# ATSAM4S2A register map
Vendor: Atmel; File version: 0
CPU: CM4 r0p1, selectable endian, no MPU, no FPU, 0x4 interrupt priority bits, 0x0 interrupts
Registers are 32-bit, read-write, reset 0x0 unless marked. A register's access mark holds for its fields unless they carry their own. Offsets are from the block's base; [hi:lo] are bit positions; {n}, {i} and the like mark numbered series.

## ADC — Analog-to-Digital Converter
Base 0x40038000; register names take the prefix ADC_
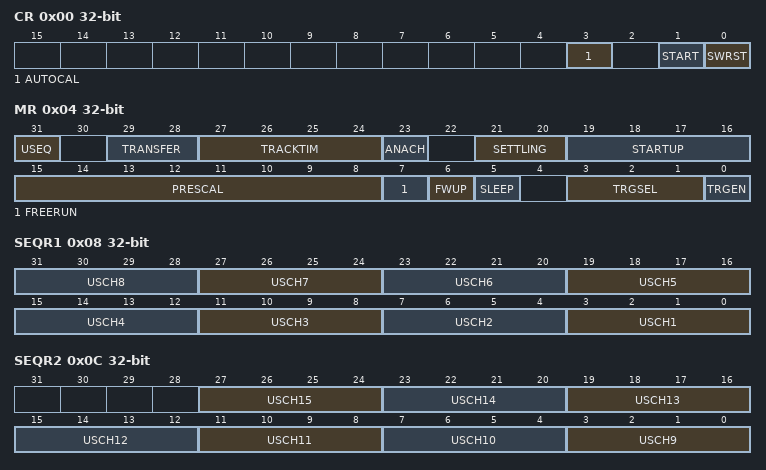
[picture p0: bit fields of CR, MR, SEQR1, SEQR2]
0x00 CR wo reset not defined — Control Register
  [3] AUTOCAL — Automatic Calibration of ADC
  [1] START — Start Conversion
  [0] SWRST — Software Reset
0x04 MR — Mode Register
  [31] USEQ — Use Sequence Enable
    0=NUM_ORDER (Normal Mode: The controller converts channels in a simple numeric order depending only on the channel index.); 1=REG_ORDER (User Sequence Mode: The sequence respects what is defined in ADC_SEQR1 and ADC_SEQR2 registers and can be used to convert the same channel several times.)
  [29:28] TRANSFER — Hold Time
  [27:24] TRACKTIM — Tracking Time
  [23] ANACH — Analog Change
    0=NONE (No analog change on channel switching: DIFF0, GAIN0 and OFF0 are used for all channels.); 1=ALLOWED (Allows different analog settings for each channel. See ADC_CGR and ADC_COR registers.)
  [21:20] SETTLING — Analog Settling Time
    0=AST3 (3 periods of ADCCLK); 1=AST5 (5 periods of ADCCLK); 2=AST9 (9 periods of ADCCLK); 3=AST17 (17 periods of ADCCLK)
  [19:16] STARTUP — Startup Time
    0=SUT0 (0 periods of ADCCLK); 1=SUT8 (8 periods of ADCCLK); 2=SUT16 (16 periods of ADCCLK); 3=SUT24 (24 periods of ADCCLK); 4=SUT64 (64 periods of ADCCLK); 5=SUT80 (80 periods of ADCCLK); 6=SUT96 (96 periods of ADCCLK); 7=SUT112 (112 periods of ADCCLK); 8=SUT512 (512 periods of ADCCLK); 9=SUT576 (576 periods of ADCCLK); 10=SUT640 (640 periods of ADCCLK); 11=SUT704 (704 periods of ADCCLK); 12=SUT768 (768 periods of ADCCLK); 13=SUT832 (832 periods of ADCCLK); 14=SUT896 (896 periods of ADCCLK); 15=SUT960 (960 periods of ADCCLK)
  [15:8] PRESCAL — Prescaler Rate Selection
  [7] FREERUN — Free Run Mode
    0=OFF (Normal Mode); 1=ON (Free Run Mode: Never wait for any trigger.)
  [6] FWUP — Fast Wake Up
    0=OFF (If SLEEP is 1, then both ADC core and reference voltage circuitry are OFF between conversions); 1=ON (If SLEEP is 1, then Fast Wake-up Sleep mode: The voltage reference is ON between conversions and ADC core is OFF)
  [5] SLEEP — Sleep Mode
    0=NORMAL (Normal Mode: The ADC core and reference voltage circuitry are kept ON between conversions.); 1=SLEEP (Sleep Mode: The wake-up time can be modified by programming FWUP bit.)
  [3:1] TRGSEL — Trigger Selection
    0=ADC_TRIG0 (External trigger); 1=ADC_TRIG1 (TIO Output of the Timer Counter Channel 0); 2=ADC_TRIG2 (TIO Output of the Timer Counter Channel 1); 3=ADC_TRIG3 (TIO Output of the Timer Counter Channel 2); 4=ADC_TRIG4 (PWM Event Line 0); 5=ADC_TRIG5 (PWM Event Line 1)
  [0] TRGEN — Trigger Enable
    0=DIS (Hardware triggers are disabled. Starting a conversion is only possible by software.); 1=EN (Hardware trigger selected by TRGSEL field is enabled.)
0x08 SEQR1 — Channel Sequence Register 1
  [4n-1:4n-4] USCH{n} (n=1..8) — User Sequence Number {n}
0x0C SEQR2 — Channel Sequence Register 2
  [4n-33:4n-36] USCH{n} (n=9..15) — User Sequence Number {n}
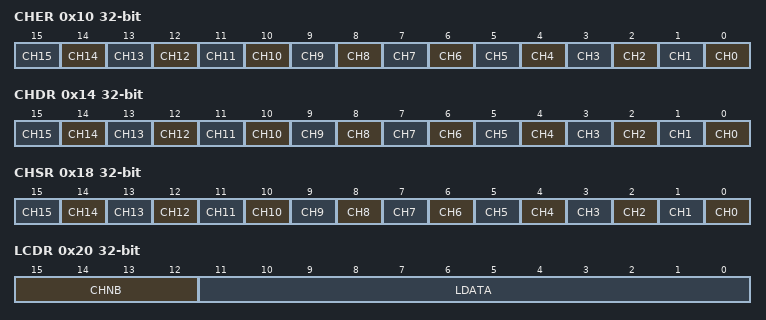
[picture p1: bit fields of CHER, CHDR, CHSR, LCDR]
0x10 CHER wo reset not defined — Channel Enable Register
  [n] CH{n} (n=0..15) — Channel {n} Enable
0x14 CHDR wo reset not defined — Channel Disable Register
  [n] CH{n} (n=0..15) — Channel {n} Disable
0x18 CHSR ro — Channel Status Register
  [n] CH{n} (n=0..15) — Channel {n} Status
0x20 LCDR ro — Last Converted Data Register
  [15:12] CHNB — Channel Number
  [11:0] LDATA — Last Data Converted
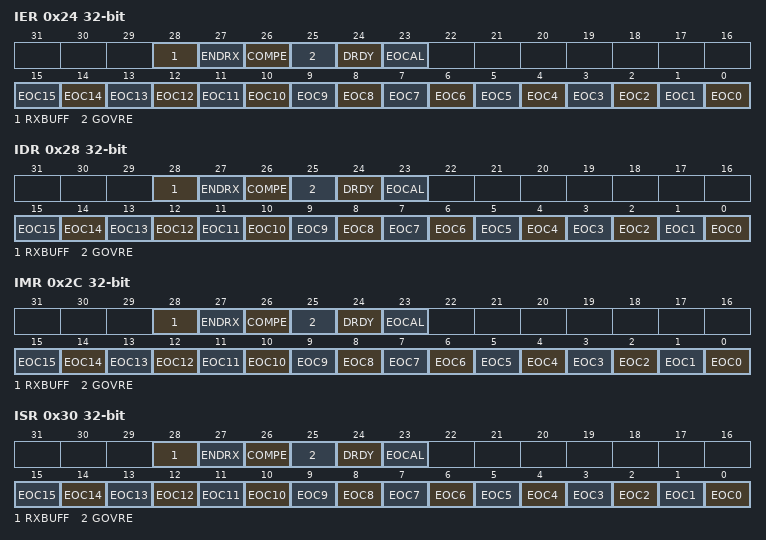
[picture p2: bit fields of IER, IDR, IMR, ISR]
0x24 IER wo reset not defined — Interrupt Enable Register
  [28] RXBUFF — Receive Buffer Full Interrupt Enable
  [27] ENDRX — End of Receive Buffer Interrupt Enable
  [26] COMPE — Comparison Event Interrupt Enable
  [25] GOVRE — General Overrun Error Interrupt Enable
  [24] DRDY — Data Ready Interrupt Enable
  [23] EOCAL — End of Calibration Sequence
  [n] EOC{n} (n=0..15) — End of Conversion Interrupt Enable {n}
0x28 IDR wo reset not defined — Interrupt Disable Register
  [28] RXBUFF — Receive Buffer Full Interrupt Disable
  [27] ENDRX — End of Receive Buffer Interrupt Disable
  [26] COMPE — Comparison Event Interrupt Disable
  [25] GOVRE — General Overrun Error Interrupt Disable
  [24] DRDY — Data Ready Interrupt Disable
  [23] EOCAL — End of Calibration Sequence
  [n] EOC{n} (n=0..15) — End of Conversion Interrupt Disable {n}
0x2C IMR ro — Interrupt Mask Register
  [28] RXBUFF — Receive Buffer Full Interrupt Mask
  [27] ENDRX — End of Receive Buffer Interrupt Mask
  [26] COMPE — Comparison Event Interrupt Mask
  [25] GOVRE — General Overrun Error Interrupt Mask
  [24] DRDY — Data Ready Interrupt Mask
  [23] EOCAL — End of Calibration Sequence
  [n] EOC{n} (n=0..15) — End of Conversion Interrupt Mask {n}
0x30 ISR ro — Interrupt Status Register
  [28] RXBUFF — Receive Buffer Full (cleared by writing ADC_RCR or ADC_RNCR)
  [27] ENDRX — End of Receive Transfer (cleared by writing ADC_RCR or ADC_RNCR)
  [26] COMPE — Comparison Event (cleared on read)
  [25] GOVRE — General Overrun Error (cleared on read)
  [24] DRDY — Data Ready (automatically set / cleared)
  [23] EOCAL — End of Calibration Sequence
  [n] EOC{n} (n=0..15) — End of Conversion {n} (automatically set / cleared)
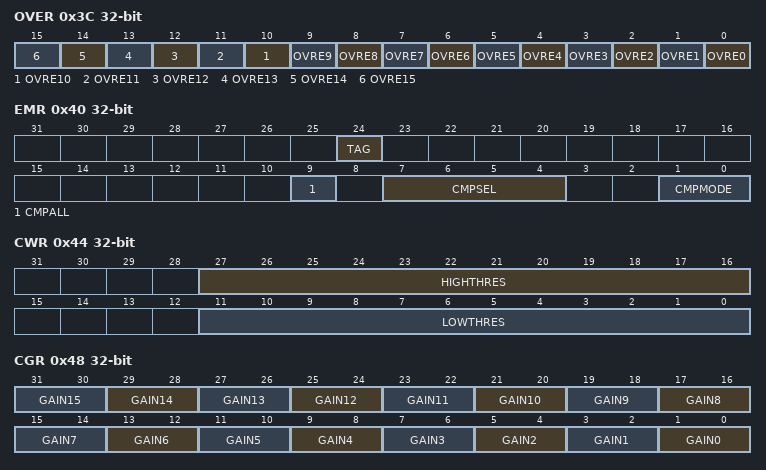
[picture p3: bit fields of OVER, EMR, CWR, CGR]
0x3C OVER ro — Overrun Status Register
  [n] OVRE{n} (n=0..15) — Overrun Error {n}
0x40 EMR — Extended Mode Register
  [24] TAG — Tag of the ADC_LCDR
  [9] CMPALL — Compare All Channels
  [7:4] CMPSEL — Comparison Selected Channel
  [1:0] CMPMODE — Comparison Mode
    0=LOW (Generates an event when the converted data is lower than the low threshold of the window.); 1=HIGH (Generates an event when the converted data is higher than the high threshold of the window.); 2=IN (Generates an event when the converted data is in the comparison window.); 3=OUT (Generates an event when the converted data is out of the comparison window.)
0x44 CWR — Compare Window Register
  [27:16] HIGHTHRES — High Threshold
  [11:0] LOWTHRES — Low Threshold
0x48 CGR — Channel Gain Register
  [all] fields
    0=SE1_DIFF0_5 (Single-ended gain = 1 (ADC_COR.DIFFx = 0), differential gain = 0.5 (ADC_COR.DIFFx = 1)); 1=SE1_DIFF1 (Single-ended gain = 1 (ADC_COR.DIFFx = 0), differential gain = 1 (ADC_COR.DIFFx = 1)); 2=SE2_DIFF2 (Single-ended gain = 2 (ADC_COR.DIFFx = 0), differential gain = 2 (ADC_COR.DIFFx = 1)); 3=SE4_DIFF2 (Single-ended gain = 4 (ADC_COR.DIFFx = 0), differential gain = 2 (ADC_COR.DIFFx = 1))
  [2n+1:2n] GAIN{n} (n=0..15) — Gain for Channel {n}
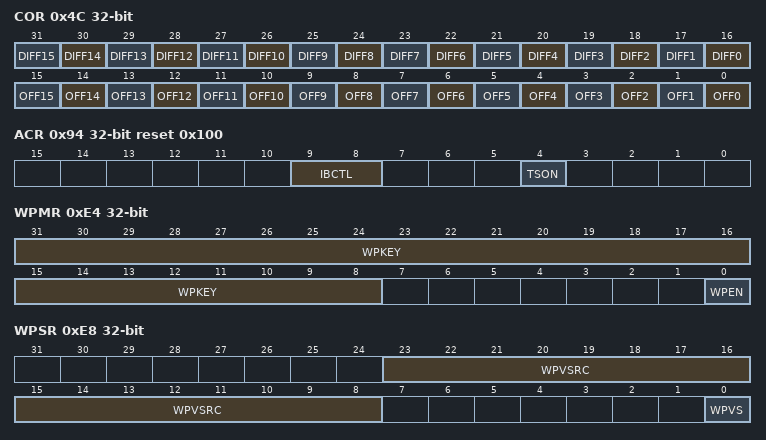
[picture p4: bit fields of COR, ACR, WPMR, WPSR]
0x4C COR — Channel Offset Register
  [n+16] DIFF{n} (n=0..15) — Differential Inputs for Channel {n}
  [n] OFF{n} (n=0..15) — Offset for Channel {n}
{0x50+4i} CDR[{i}] ro reset not defined (i=0..15) — Channel Data Register
  [11:0] DATA — Converted Data
0x94 ACR reset 0x100 — Analog Control Register
  [9:8] IBCTL — ADC Bias Current Control
  [4] TSON — Temperature Sensor On
0xE4 WPMR — Write Protection Mode Register
  [31:8] WPKEY — Write Protection Key
    0x414443=PASSWD (Writing any other value in this field aborts the write operation of the WPEN bit.Always reads as 0)
  [0] WPEN — Write Protection Enable
0xE8 WPSR ro — Write Protection Status Register
  [23:8] WPVSRC — Write Protection Violation Source
  [0] WPVS — Write Protection Violation Status
0x100 RPR — Receive Pointer Register
  [31:0] RXPTR
0x104 RCR — Receive Counter Register
  [15:0] RXCTR
0x110 RNPR — Receive Next Pointer Register
  [31:0] RXNPTR — Receive Next Pointer
0x114 RNCR — Receive Next Counter Register
  [15:0] RXNCTR — Receive Next Counter
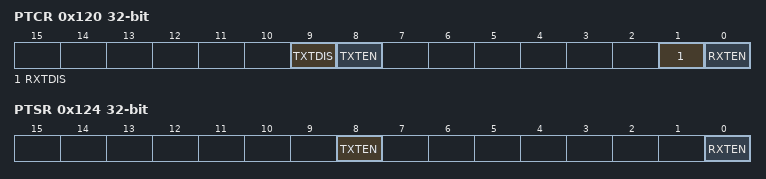
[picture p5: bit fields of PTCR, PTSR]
0x120 PTCR wo reset not defined — Transfer Control Register
  [9] TXTDIS — Transmitter Transfer Disable
  [8] TXTEN — Transmitter Transfer Enable
  [1] RXTDIS — Receiver Transfer Disable
  [0] RXTEN — Receiver Transfer Enable
0x124 PTSR ro — Transfer Status Register
  [8] TXTEN — Transmitter Transfer Enable
  [0] RXTEN — Receiver Transfer Enable
